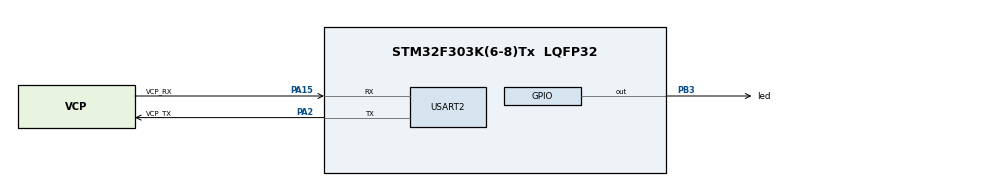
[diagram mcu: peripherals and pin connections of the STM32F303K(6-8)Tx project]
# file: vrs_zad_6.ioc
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Mcu.Family=STM32F3
Mcu.Name=STM32F303K(6-8)Tx
Mcu.Package=LQFP32
NVIC.PriorityGroup=NVIC_PRIORITYGROUP_4
NVIC.USART2_IRQn=true\:0\:0\:false\:false\:true\:true\:true
PA13.GPIO_Label=SWDIO
PA13.Mode=Serial_Wire
PA13.Signal=SYS_JTMS-SWDIO
PA14.GPIO_Label=SWCLK
PA14.Mode=Serial_Wire
PA14.Signal=SYS_JTCK-SWCLK
PA15.GPIO_Label=VCP_RX
PA15.Mode=Asynchronous
PA15.Signal=USART2_RX
PA2.GPIO_Label=VCP_TX
PA2.Mode=Asynchronous
PA2.Signal=USART2_TX
PB3.GPIO_Label=led
PB3.Signal=GPIO_Output
PF0\ /\ OSC_IN.GPIO_Label=MCO
PF0\ /\ OSC_IN.Mode=HSE-External-Clock-Source
PF0\ /\ OSC_IN.Signal=RCC_OSC_IN
ProjectManager.HeapSize=0x200
ProjectManager.StackSize=0x400
ProjectManager.TargetToolchain=STM32CubeIDE
RCC.AHBFreq_Value=8000000
RCC.APB1Freq_Value=8000000
RCC.APB2Freq_Value=8000000
RCC.CortexFreq_Value=8000000
RCC.HSE_VALUE=8000000
RCC.HSI_VALUE=8000000
RCC.SYSCLKFreq_VALUE=8000000
USART2.VirtualMode-Asynchronous=VM_ASYNC
board=NUCLEO-F303K8

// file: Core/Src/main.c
/* USER CODE BEGIN Header */
/**
  ******************************************************************************
  * @file           : main.c
  * @brief          : Main program body
  ******************************************************************************
  * @attention
  *
  * <h2><center>&copy; Copyright (c) 2020 STMicroelectronics.
  * All rights reserved.</center></h2>
  *
  * This software component is licensed by ST under BSD 3-Clause license,
  * the "License"; You may not use this file except in compliance with the
  * License. You may obtain a copy of the License at:
  *                        opensource.org/licenses/BSD-3-Clause
  *
  ******************************************************************************
  */
/* USER CODE END Header */
#include "main.h"

/* USER CODE BEGIN PTD */
#define timeout_serial 	5 // 5 sec on serial timeout
#define timeout_enable 	0x1 // first bit of 'mode' memory

/* USER CODE END PTD */

/* USER CODE BEGIN PV */
uint16_t milisecs=0;
uint16_t msec_1000=0;
uint16_t secs=0;

uint8_t mode=0; //0.bit timeout enable
uint8_t readed_byte=0;
const uint8_t passwd_on[]={'l','e','d','O','N','\0'};
uint8_t pass_passed_on_cnt=0;
#define passwd_on_len 		4
const uint8_t passwd_off[]={'l','e','d','O','F','F','\0'};
uint8_t pass_passed_off_cnt=0;
#define passwd_off_len 		5
uint8_t send_buff[]={'t','i','m','e','o','u','t',' ',' ',' ','\0'};
uint8_t send_buff_sended=0;
uint8_t send_buff_len=0;

/* USER CODE END PV */

void SystemClock_Config(void);
static void MX_GPIO_Init(void);
static void MX_USART2_UART_Init(void);
/* USER CODE BEGIN PFP */
void goto_sleep(void);
void inic_100ms_timer(void);
void inic_uart2_serial(void);
void my_strcpy(uint8_t * dest, uint8_t * from, uint8_t *copied);

/* USER CODE END PFP */

int main(void)
{
  /* USER CODE BEGIN 1 */
//	uint16_t cnt;
  /* USER CODE END 1 */

  /* MCU Configuration--------------------------------------------------------*/

  /* Reset of all peripherals, Initializes the Flash interface and the Systick. */

  LL_APB2_GRP1_EnableClock(LL_APB2_GRP1_PERIPH_SYSCFG);
  LL_APB1_GRP1_EnableClock(LL_APB1_GRP1_PERIPH_PWR);

  NVIC_SetPriorityGrouping(NVIC_PRIORITYGROUP_4);

  /* System interrupt init*/

  /* Configure the system clock */
  SystemClock_Config();

  /* Initialize all configured peripherals */
  MX_GPIO_Init();
  MX_USART2_UART_Init();
  /* USER CODE BEGIN 2 */
  //led_GPIO_Port->BSRR |= led_Pin;
  inic_100ms_timer();

  //inic_uart2_serial();
  LL_USART_EnableIT_RXNE(USART2);
  //LL_USART_EnableIT_TXE(USART2);
  my_strcpy(send_buff,(uint8_t *) "Ready \0", &send_buff_len);
  LL_USART_EnableIT_TXE(USART2);
  /* USER CODE END 2 */

  /* Infinite loop */
  /* USER CODE BEGIN WHILE */
  while (1)
  {
	  __WFI();
	  //goto_sleep();
	  //for (cnt=0;cnt<=65000;){
		//  cnt++;
	  //}
	  //LL_GPIO_TogglePin(led_GPIO_Port,led_Pin);
    /* USER CODE END WHILE */

  }
}

void SystemClock_Config(void)
{
  LL_FLASH_SetLatency(LL_FLASH_LATENCY_0);
  while(LL_FLASH_GetLatency()!= LL_FLASH_LATENCY_0)
  {
  }
  LL_RCC_HSI_Enable();

   /* Wait till HSI is ready */
  while(LL_RCC_HSI_IsReady() != 1)
  {

  }
  LL_RCC_HSI_SetCalibTrimming(16);
  LL_RCC_SetAHBPrescaler(LL_RCC_SYSCLK_DIV_1);
  LL_RCC_SetAPB1Prescaler(LL_RCC_APB1_DIV_1);
  LL_RCC_SetAPB2Prescaler(LL_RCC_APB1_DIV_1);
  LL_RCC_SetSysClkSource(LL_RCC_SYS_CLKSOURCE_HSI);

   /* Wait till System clock is ready */
  while(LL_RCC_GetSysClkSource() != LL_RCC_SYS_CLKSOURCE_STATUS_HSI)
  {

  }
  LL_Init1msTick(8000000);
  LL_SetSystemCoreClock(8000000);
}

static void MX_USART2_UART_Init(void)
{

  LL_USART_InitTypeDef USART_InitStruct = {0};

  LL_GPIO_InitTypeDef GPIO_InitStruct = {0};

  /* Peripheral clock enable */
  LL_APB1_GRP1_EnableClock(LL_APB1_GRP1_PERIPH_USART2);

  LL_AHB1_GRP1_EnableClock(LL_AHB1_GRP1_PERIPH_GPIOA);
  /**USART2 GPIO Configuration
  PA2   ------> USART2_TX
  PA15   ------> USART2_RX
  */
  GPIO_InitStruct.Pin = VCP_TX_Pin|VCP_RX_Pin;
  GPIO_InitStruct.Mode = LL_GPIO_MODE_ALTERNATE;
  GPIO_InitStruct.Speed = LL_GPIO_SPEED_FREQ_HIGH;
  GPIO_InitStruct.OutputType = LL_GPIO_OUTPUT_PUSHPULL;
  GPIO_InitStruct.Pull = LL_GPIO_PULL_NO;
  GPIO_InitStruct.Alternate = LL_GPIO_AF_7;
  LL_GPIO_Init(GPIOA, &GPIO_InitStruct);

  /* USART2 interrupt Init */
  NVIC_SetPriority(USART2_IRQn, NVIC_EncodePriority(NVIC_GetPriorityGrouping(),0, 0));
  NVIC_EnableIRQ(USART2_IRQn);

  USART_InitStruct.BaudRate = 38400;
  USART_InitStruct.DataWidth = LL_USART_DATAWIDTH_8B;
  USART_InitStruct.StopBits = LL_USART_STOPBITS_1;
  USART_InitStruct.Parity = LL_USART_PARITY_NONE;
  USART_InitStruct.TransferDirection = LL_USART_DIRECTION_TX_RX;
  USART_InitStruct.HardwareFlowControl = LL_USART_HWCONTROL_NONE;
  USART_InitStruct.OverSampling = LL_USART_OVERSAMPLING_16;
  LL_USART_Init(USART2, &USART_InitStruct);
  LL_USART_DisableIT_CTS(USART2);
  LL_USART_ConfigAsyncMode(USART2);
  LL_USART_Enable(USART2);

}

static void MX_GPIO_Init(void)
{
  LL_GPIO_InitTypeDef GPIO_InitStruct = {0};

  /* GPIO Ports Clock Enable */
  LL_AHB1_GRP1_EnableClock(LL_AHB1_GRP1_PERIPH_GPIOF);
  LL_AHB1_GRP1_EnableClock(LL_AHB1_GRP1_PERIPH_GPIOA);
  LL_AHB1_GRP1_EnableClock(LL_AHB1_GRP1_PERIPH_GPIOB);

  /**/
  LL_GPIO_ResetOutputPin(led_GPIO_Port, led_Pin);

  /**/
  GPIO_InitStruct.Pin = led_Pin;
  GPIO_InitStruct.Mode = LL_GPIO_MODE_OUTPUT;
  GPIO_InitStruct.Speed = LL_GPIO_SPEED_FREQ_LOW;
  GPIO_InitStruct.OutputType = LL_GPIO_OUTPUT_PUSHPULL;
  GPIO_InitStruct.Pull = LL_GPIO_PULL_NO;
  LL_GPIO_Init(led_GPIO_Port, &GPIO_InitStruct);

}

/* USER CODE BEGIN 4 */
void inic_100ms_timer(void){
	// enalbe clock
	RCC->APB1ENR |= RCC_APB1ENR_TIM2EN;

	//config
	TIM2->PSC = 0;
	TIM2->ARR = 7999;
	TIM2->CR1 |= TIM_CR1_URS;
	TIM2->DIER |= TIM_DIER_UIE;
	TIM2->EGR |= TIM_EGR_UG;
	// enable timer
	//TIM2->CR1 |=TIM_CR1_CEN;

	//nvic
	NVIC_EnableIRQ(TIM2_IRQn);
	TIM2->CR1 |=TIM_CR1_CEN;
	milisecs=0;

}

void my_strcpy(uint8_t * dest, uint8_t * from, uint8_t *copied){
	uint8_t cnt=0;
	for (cnt=0;*(from+cnt)!='\0';cnt++)
		*(dest+cnt)=*(from+cnt);
	*copied=cnt;
}

void TIM2_IRQHandler(void){

	if (++milisecs >= 1000)
		{milisecs=0;

		//msec_1000++;
		// print the led state
		//LL_GPIO_TogglePin(led_GPIO_Port, led_Pin);
		if ((led_GPIO_Port->ODR )&led_Pin){
			my_strcpy(send_buff,(uint8_t *) "led ON \0", &send_buff_len);
		}
		else{
			my_strcpy(send_buff,(uint8_t *) "led OFF \0", &send_buff_len);
		}
		LL_USART_EnableIT_TXE(USART2);
		//LL_GPIO_TogglePin(led_GPIO_Port, led_Pin);
		if (mode & timeout_enable )
			{
			if (++secs >= timeout_serial)
				{
				secs=0;
				// timeout
				my_strcpy(send_buff,(uint8_t *) "Timeout \0", &send_buff_len);
				LL_USART_EnableIT_TXE(USART2);
				pass_passed_on_cnt=0;
				pass_passed_off_cnt=0;
				mode &=~(timeout_enable);
				}
			}
		}
	TIM2->SR &= ~(TIM_SR_UIF);
}

/* USER CODE END 4 */

void Error_Handler(void)
{
}

/************************ (C) COPYRIGHT STMicroelectronics *****END OF FILE****/
